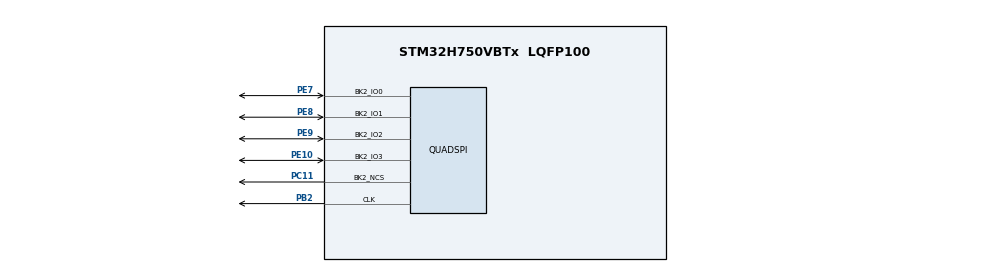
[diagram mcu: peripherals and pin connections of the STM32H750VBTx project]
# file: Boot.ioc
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CORTEX_M7.CPU_DCache=Enabled
CORTEX_M7.CPU_ICache=Enabled
Mcu.Family=STM32H7
Mcu.Name=STM32H750VBTx
Mcu.Package=LQFP100
NVIC.PriorityGroup=NVIC_PRIORITYGROUP_4
PB2.GPIO_Speed=GPIO_SPEED_FREQ_VERY_HIGH
PB2.Mode=Single Bank 2
PB2.Signal=QUADSPI_CLK
PC11.GPIO_Speed=GPIO_SPEED_FREQ_VERY_HIGH
PC11.Mode=Single Bank 2
PC11.Signal=QUADSPI_BK2_NCS
PC14-OSC32_IN\ (OSC32_IN).Mode=LSE-External-Oscillator
PC14-OSC32_IN\ (OSC32_IN).Signal=RCC_OSC32_IN
PC15-OSC32_OUT\ (OSC32_OUT).Mode=LSE-External-Oscillator
PC15-OSC32_OUT\ (OSC32_OUT).Signal=RCC_OSC32_OUT
PE10.GPIO_Speed=GPIO_SPEED_FREQ_VERY_HIGH
PE10.Mode=Single Bank 2
PE10.Signal=QUADSPI_BK2_IO3
PE7.GPIO_Speed=GPIO_SPEED_FREQ_VERY_HIGH
PE7.Mode=Single Bank 2
PE7.Signal=QUADSPI_BK2_IO0
PE8.GPIO_Speed=GPIO_SPEED_FREQ_VERY_HIGH
PE8.Mode=Single Bank 2
PE8.Signal=QUADSPI_BK2_IO1
PE9.GPIO_Speed=GPIO_SPEED_FREQ_VERY_HIGH
PE9.Mode=Single Bank 2
PE9.Signal=QUADSPI_BK2_IO2
PH0-OSC_IN\ (PH0).Mode=HSE-External-Oscillator
PH0-OSC_IN\ (PH0).Signal=RCC_OSC_IN
PH1-OSC_OUT\ (PH1).Mode=HSE-External-Oscillator
PH1-OSC_OUT\ (PH1).Signal=RCC_OSC_OUT
ProjectManager.HeapSize=0x1200
ProjectManager.StackSize=0x1200
ProjectManager.TargetToolchain=EWARM V8
QUADSPI.ChipSelectHighTime=QSPI_CS_HIGH_TIME_6_CYCLE
QUADSPI.ClockMode=QSPI_CLOCK_MODE_3
QUADSPI.ClockPrescaler=1
QUADSPI.FifoThreshold=24
QUADSPI.FlashSize=24
QUADSPI.SampleShifting=QSPI_SAMPLE_SHIFTING_HALFCYCLE
RCC.ADCFreq_Value=50390625
RCC.APB1Freq_Value=120000000
RCC.APB2Freq_Value=120000000
RCC.APB3Freq_Value=120000000
RCC.APB4Freq_Value=120000000
RCC.CortexFreq_Value=480000000
RCC.D1PPRE=RCC_APB3_DIV2
RCC.D2PPRE1=RCC_APB1_DIV2
RCC.D2PPRE2=RCC_APB2_DIV2
RCC.D3PPRE=RCC_APB4_DIV2
RCC.DIVM1=5
RCC.DIVN1=192
RCC.HCLKFreq_Value=240000000
RCC.HPRE=RCC_HCLK_DIV2
RCC.PLLSourceVirtual=RCC_PLLSOURCE_HSE
RCC.RTCClockSelection=RCC_RTCCLKSOURCE_LSE
RCC.SYSCLKFreq_VALUE=480000000
RCC.SYSCLKSource=RCC_SYSCLKSOURCE_PLLCLK
RCC.USBFreq_Value=480000000
RTC.Format=RTC_FORMAT_BIN
RTC.WeekDay=RTC_WEEKDAY_FRIDAY
RTC.Year=21
VP_RTC_VS_RTC_Activate.Mode=RTC_Enabled
VP_RTC_VS_RTC_Calendar.Mode=RTC_Calendar
board=custom

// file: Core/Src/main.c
/* USER CODE BEGIN Header */
/**
  ******************************************************************************
  * @file           : main.c
  * @brief          : Main program body
  ******************************************************************************
  * @attention
  *
  * <h2><center>&copy; Copyright (c) 2021 STMicroelectronics.
  * All rights reserved.</center></h2>
  *
  * This software component is licensed by ST under BSD 3-Clause license,
  * the "License"; You may not use this file except in compliance with the
  * License. You may obtain a copy of the License at:
  *                        opensource.org/licenses/BSD-3-Clause
  *
  ******************************************************************************
  */
/* USER CODE END Header */
#include "main.h"
#include "quadspi.h"
#include "rtc.h"
#include "gpio.h"

/* USER CODE BEGIN Includes */
#include "w25qxx.h"
/* USER CODE END Includes */

void SystemClock_Config(void);
/* USER CODE BEGIN PFP */

typedef  void (*pFunction)(void);
#define ApplicationAddress    0x90000000
pFunction Jump_To_Application;
uint32_t JumpAddress;

void Jump2App(void)
{
    JumpAddress = *(__IO uint32_t *) (ApplicationAddress + 4);
    Jump_To_Application = (pFunction) JumpAddress;
    __set_MSP(*(__IO uint32_t *) ApplicationAddress);
    Jump_To_Application();
}

/* USER CODE END PFP */

int main(void)
{

  /* Enable I-Cache---------------------------------------------------------*/
  SCB_EnableICache();

  /* Enable D-Cache---------------------------------------------------------*/
  SCB_EnableDCache();

  /* MCU Configuration--------------------------------------------------------*/

  /* Reset of all peripherals, Initializes the Flash interface and the Systick. */
  HAL_Init();

  /* Configure the system clock */
  SystemClock_Config();

  /* Initialize all configured peripherals */
  MX_GPIO_Init();
  MX_QUADSPI_Init();
  MX_RTC_Init();
  /* USER CODE BEGIN 2 */
  W25QXX_Init();
  W25QXX_EnableMemoryMapped();
  Jump2App();
  /* USER CODE END 2 */

  /* Infinite loop */
    while (1)
    {

    }
}

void SystemClock_Config(void)
{
  RCC_OscInitTypeDef RCC_OscInitStruct = {0};
  RCC_ClkInitTypeDef RCC_ClkInitStruct = {0};

  /** Supply configuration update enable
  */
  HAL_PWREx_ConfigSupply(PWR_LDO_SUPPLY);
  /** Configure the main internal regulator output voltage
  */
  __HAL_PWR_VOLTAGESCALING_CONFIG(PWR_REGULATOR_VOLTAGE_SCALE0);

  while(!__HAL_PWR_GET_FLAG(PWR_FLAG_VOSRDY)) {}
  /** Configure LSE Drive Capability
  */
  HAL_PWR_EnableBkUpAccess();
  __HAL_RCC_LSEDRIVE_CONFIG(RCC_LSEDRIVE_LOW);
  /** Initializes the RCC Oscillators according to the specified parameters
  * in the RCC_OscInitTypeDef structure.
  */
  RCC_OscInitStruct.OscillatorType = RCC_OSCILLATORTYPE_HSE|RCC_OSCILLATORTYPE_LSE;
  RCC_OscInitStruct.HSEState = RCC_HSE_ON;
  RCC_OscInitStruct.LSEState = RCC_LSE_ON;
  RCC_OscInitStruct.PLL.PLLState = RCC_PLL_ON;
  RCC_OscInitStruct.PLL.PLLSource = RCC_PLLSOURCE_HSE;
  RCC_OscInitStruct.PLL.PLLM = 5;
  RCC_OscInitStruct.PLL.PLLN = 192;
  RCC_OscInitStruct.PLL.PLLP = 2;
  RCC_OscInitStruct.PLL.PLLQ = 2;
  RCC_OscInitStruct.PLL.PLLR = 2;
  RCC_OscInitStruct.PLL.PLLRGE = RCC_PLL1VCIRANGE_2;
  RCC_OscInitStruct.PLL.PLLVCOSEL = RCC_PLL1VCOWIDE;
  RCC_OscInitStruct.PLL.PLLFRACN = 0;
  if (HAL_RCC_OscConfig(&RCC_OscInitStruct) != HAL_OK)
  {
    Error_Handler();
  }
  /** Initializes the CPU, AHB and APB buses clocks
  */
  RCC_ClkInitStruct.ClockType = RCC_CLOCKTYPE_HCLK|RCC_CLOCKTYPE_SYSCLK
                              |RCC_CLOCKTYPE_PCLK1|RCC_CLOCKTYPE_PCLK2
                              |RCC_CLOCKTYPE_D3PCLK1|RCC_CLOCKTYPE_D1PCLK1;
  RCC_ClkInitStruct.SYSCLKSource = RCC_SYSCLKSOURCE_PLLCLK;
  RCC_ClkInitStruct.SYSCLKDivider = RCC_SYSCLK_DIV1;
  RCC_ClkInitStruct.AHBCLKDivider = RCC_HCLK_DIV2;
  RCC_ClkInitStruct.APB3CLKDivider = RCC_APB3_DIV2;
  RCC_ClkInitStruct.APB1CLKDivider = RCC_APB1_DIV2;
  RCC_ClkInitStruct.APB2CLKDivider = RCC_APB2_DIV2;
  RCC_ClkInitStruct.APB4CLKDivider = RCC_APB4_DIV2;

  if (HAL_RCC_ClockConfig(&RCC_ClkInitStruct, FLASH_LATENCY_4) != HAL_OK)
  {
    Error_Handler();
  }
}

void Error_Handler(void)
{
    __disable_irq();
    while (1)
    {
    }
}

/************************ (C) COPYRIGHT STMicroelectronics *****END OF FILE****/
